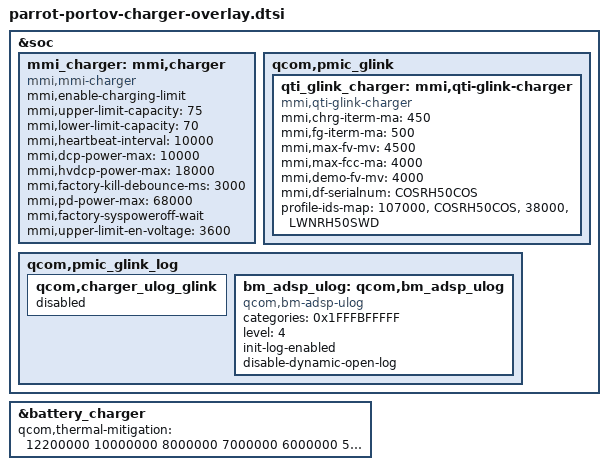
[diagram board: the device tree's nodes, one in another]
&soc {
	mmi_charger: mmi,charger {
		compatible = "mmi,mmi-charger";
		mmi,enable-charging-limit;
		mmi,upper-limit-capacity = <75>;
		mmi,lower-limit-capacity = <70>;
		mmi,heartbeat-interval = <10000>;
		mmi,dcp-power-max = <10000>;
		mmi,hvdcp-power-max = <18000>;
		mmi,factory-kill-debounce-ms = <3000>;
		mmi,pd-power-max = <68000>;
		mmi,factory-syspoweroff-wait;
		mmi,upper-limit-en-voltage = <3600>;
	};

	qcom,pmic_glink {
		status = "ok";
		qti_glink_charger: mmi,qti-glink-charger {
			compatible = "mmi,qti-glink-charger";
			mmi,chrg-iterm-ma = <450>;
			mmi,fg-iterm-ma = <500>;
			mmi,max-fv-mv = <4500>;
			mmi,max-fcc-ma = <4000>;
			mmi,demo-fv-mv = <4000>;
			mmi,df-serialnum = "COSRH50COS";
			profile-ids-map = "107000", "COSRH50COS","38000","LWNRH50SWD";
		};
	};

	qcom,pmic_glink_log {
		qcom,charger_ulog_glink {
			status = "disabled";
		};
		bm_adsp_ulog: qcom,bm_adsp_ulog {
			compatible = "qcom,bm-adsp-ulog";
			categories = /bits/ 64 <0x1FFFBFFFFF>;
			level = <4>;
			init-log-enabled;
			disable-dynamic-open-log;
		};
	};
};


&battery_charger {
	qcom,thermal-mitigation = <12200000 10000000 8000000 7000000 6000000 5000000 4000000 3500000 3000000 1500000 1000000 500000 100000>;
};
